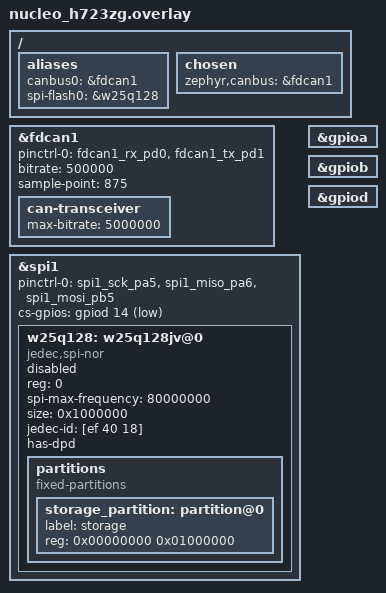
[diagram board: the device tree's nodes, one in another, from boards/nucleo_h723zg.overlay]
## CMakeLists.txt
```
# SPDX-License-Identifier: Apache-2.0

cmake_minimum_required(VERSION 3.20.0)

# Roadio firmware application
find_package(Zephyr REQUIRED HINTS $ENV{ZEPHYR_BASE})
project(roadio_firmware VERSION 0.1.0)

# Application source files
target_sources(app PRIVATE
    src/main.c
)

# Include directories
# target_include_directories(app PRIVATE
#     src/
# )
```

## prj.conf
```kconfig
# Roadio Firmware Configuration
# Zephyr v4.3.0 - Nucleo-H723ZG

# ========================================
# Kernel Configuration
# ========================================
CONFIG_MAIN_STACK_SIZE=4096
CONFIG_HEAP_MEM_POOL_SIZE=8192

# ========================================
# Logging Configuration
# ========================================
CONFIG_LOG=y
CONFIG_LOG_MODE_IMMEDIATE=y
CONFIG_LOG_DEFAULT_LEVEL=3

# ========================================
# Console/Shell Configuration
# ========================================
CONFIG_CONSOLE=y
CONFIG_UART_CONSOLE=y
CONFIG_SERIAL=y

# Optional: Enable shell for debugging/testing
CONFIG_SHELL=y
CONFIG_SHELL_BACKEND_SERIAL=y
CONFIG_SHELL_PROMPT_UART="roadio:~$ "

# ========================================
# CAN/FDCAN Configuration
# ========================================
CONFIG_CAN=y
CONFIG_CAN_INIT_PRIORITY=80

# Enable CAN shell for testing (optional - can disable in production)
CONFIG_CAN_SHELL=y

# CAN ISO-TP (Transport Protocol) for multi-frame messages
# Useful for UDS/OBD diagnostics
CONFIG_ISOTP=y

# ========================================
# GPIO Configuration
# ========================================
CONFIG_GPIO=y

# ========================================
# SPI Configuration (for W25Q128 flash)
# ========================================
CONFIG_SPI=y

# ========================================
# Flash & Storage Configuration
# ========================================
CONFIG_FLASH=y
CONFIG_FLASH_MAP=y
CONFIG_FLASH_PAGE_LAYOUT=y

# SPI NOR flash support (for W25Q128)
CONFIG_SPI_NOR=y
CONFIG_SPI_NOR_FLASH_LAYOUT_PAGE_SIZE=4096

# File system support
CONFIG_FILE_SYSTEM=y
CONFIG_FILE_SYSTEM_LITTLEFS=y

# Non-Volatile Storage (NVS) - lightweight key-value storage
CONFIG_NVS=y
CONFIG_NVS_LOG_LEVEL_DBG=n

# Optional: Flash simulator for testing (disable for production)
# CONFIG_FLASH_SIMULATOR=y

# ========================================
# Networking Configuration (for future use)
# ========================================
# Uncomment when adding network features (nRF7002 Wi-Fi, etc.)
# CONFIG_NETWORKING=y
# CONFIG_NET_IPV4=y
# CONFIG_NET_IPV6=y
# CONFIG_NET_TCP=y
# CONFIG_NET_UDP=y
# CONFIG_NET_DHCPV4=y

# ========================================
# USB Configuration (optional)
# ========================================
# Uncomment if using USB for console or data transfer
# CONFIG_USB_DEVICE_STACK=y
# CONFIG_USB_DEVICE_PRODUCT="Roadio OBD-II Device"
# CONFIG_USB_DEVICE_VID=0x2FE3
# CONFIG_USB_DEVICE_PID=0x0001

# ========================================
# Power Management (optional)
# ========================================
# Uncomment for low-power applications
# CONFIG_PM=y
# CONFIG_PM_DEVICE=y

# ========================================
# Watchdog (recommended for production)
# ========================================
# CONFIG_WATCHDOG=y
# CONFIG_WDT_DISABLE_AT_BOOT=n

# ========================================
# System Clock Configuration
# ========================================
# STM32H7 can run up to 550 MHz
# Default is usually fine, adjust if needed
# CONFIG_SYS_CLOCK_HW_CYCLES_PER_SEC=550000000

# ========================================
# Debug Configuration
# ========================================
# Enable for development, disable for production
CONFIG_DEBUG=y
CONFIG_DEBUG_OPTIMIZATIONS=y

# Assert configuration
CONFIG_ASSERT=y
CONFIG_ASSERT_LEVEL=2

# ========================================
# Thread Configuration
# ========================================
CONFIG_THREAD_NAME=y
CONFIG_THREAD_STACK_INFO=y

# ========================================
# Memory Protection (optional)
# ========================================
# CONFIG_ARM_MPU=y

# ========================================
# POSIX API (if needed for portability)
# ========================================
# CONFIG_POSIX_API=y
```

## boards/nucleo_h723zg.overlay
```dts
/*
 * Devicetree overlay for Nucleo-H723ZG board
 * Roadio hardware configuration
 *
 * Hardware components:
 * - SN65HVD230 CAN transceiver (connected to FDCAN1)
 * - W25Q128 external SPI flash (128 Mbit / 16 MB)
 * - LM2596 DC-DC buck converter (external power management)
 *
 * IMPORTANT: Verify actual pin connections match your hardware wiring!
 * Update pin assignments below to match your specific setup.
 */

/ {
	aliases {
		/* Define aliases for easy reference in application code */
		canbus0 = &fdcan1;
		spi-flash0 = &w25q128;
	};

	/* Choose CAN as the default console (optional - can use UART instead) */
	chosen {
		zephyr,canbus = &fdcan1;
	};
};

/*
 * FDCAN1 Configuration
 *
 * Default pins (verify against your actual wiring):
 * - TX: PD1 (Arduino D54)
 * - RX: PD0 (Arduino D55)
 *
 * SN65HVD230 transceiver connections:
 *   STM32 TX (PD1) -> CAN TX (pin 1)
 *   STM32 RX (PD0) -> CAN RX (pin 4)
 *   CAN H/L -> to vehicle OBD-II via DB9 adapter
 *
 * NOTE: OBD-II CAN is typically on pins 6 (CAN-H) and 14 (CAN-L) of the OBD connector.
 * Verify your DB9<->OBD2 cable pinout!
 */
&fdcan1 {
	status = "okay";
	pinctrl-0 = <&fdcan1_rx_pd0 &fdcan1_tx_pd1>;
	pinctrl-names = "default";

	/*
	 * CAN bus timing configuration:
	 * - bitrate: 500 kbit/s (standard OBD-II speed)
	 * - sample-point: 87.5% (recommended for automotive CAN)
	 * Adjust if your vehicle uses different speed (125k, 250k, 500k, 1000k common)
	 * If not specified, defaults to CONFIG_CAN_DEFAULT_BITRATE (usually 125k or 500k)
	 */
	bitrate = <500000>;
	sample-point = <875>;

	can-transceiver {
		max-bitrate = <5000000>; /* SN65HVD230 supports up to 1 Mbps for CAN, 5Mbps for CAN-FD */
	};
};

/*
 * SPI1 Configuration for W25Q128 External Flash
 *
 * Default pins (verify against your actual wiring):
 * - SCK:  PA5  (Arduino D13, Morpho CN7-10)
 * - MISO: PA6  (Arduino D12, Morpho CN7-12)
 * - MOSI: PB5  (Arduino D4, Morpho CN7-29)
 * - CS:   PD14 (Morpho CN7-16) - adjust as needed
 *
 * Note: Board default uses PB5 for MOSI. If using Arduino connector,
 * you may want PA7 instead - change pinctrl-0 accordingly.
 *
 * W25Q128 module connections:
 *   VCC  -> 3.3V
 *   GND  -> GND
 *   DI   -> MOSI (PB5)
 *   DO   -> MISO (PA6)
 *   CLK  -> SCK  (PA5)
 *   CS   -> PD14 (or your chosen CS pin)
 */
&spi1 {
	status = "okay";
	pinctrl-0 = <&spi1_sck_pa5 &spi1_miso_pa6 &spi1_mosi_pb5>;
	pinctrl-names = "default";
	cs-gpios = <&gpiod 14 GPIO_ACTIVE_LOW>;  /* CS on PD14 - adjust to match your wiring */

	w25q128: w25q128jv@0 {
		compatible = "jedec,spi-nor";
		reg = <0>;
		spi-max-frequency = <80000000>;  /* W25Q128JV supports up to 133 MHz, start conservative */
		size = <0x1000000>;  /* 128 Mbit = 16 MB = 0x1000000 bytes */
		jedec-id = [ef 40 18];  /* Winbond W25Q128 JEDEC ID */
		has-dpd;  /* Deep Power-Down support */
		status = "disabled";  /* Enable after wiring up hardware */

		/*
		 * Flash partitions for storage
		 * Adjust based on your firmware/data storage needs
		 */
		partitions {
			compatible = "fixed-partitions";
			#address-cells = <1>;
			#size-cells = <1>;

			/*
			 * Storage partition for application data
			 * Using LittleFS or NVS (Non-Volatile Storage)
			 * Size: 16 MB (entire flash for now)
			 */
			storage_partition: partition@0 {
				label = "storage";
				reg = <0x00000000 0x01000000>;  /* 16 MB */
			};
		};
	};
};

/*
 * Optional: Configure USART3 for debug console (if not using CAN)
 * Default Nucleo serial is on USART3 via ST-Link USB
 *
 * Uncomment if you want UART debug output:
 */
/*
&usart3 {
	status = "okay";
	pinctrl-0 = <&usart3_tx_pd8 &usart3_rx_pd9>;
	pinctrl-names = "default";
	current-speed = <115200>;
};
*/

/*
 * Enable GPIO ports used by peripherals
 */
&gpioa {
	status = "okay";
};

&gpiob {
	status = "okay";
};

&gpiod {
	status = "okay";
};

/*
 * Optional: QSPI configuration for W25Q128
 *
 * If you want to use QSPI instead of SPI for faster flash access,
 * uncomment and configure this section. Requires different wiring:
 *
 * QSPI pins on STM32H723:
 *   CLK:  PB2
 *   NCS:  PB6
 *   IO0:  PD11
 *   IO1:  PD12
 *   IO2:  PE2
 *   IO3:  PD13
 */
/*
&quadspi {
	status = "okay";
	pinctrl-0 = <&quadspi_clk_pb2 &quadspi_bk1_ncs_pb6
	             &quadspi_bk1_io0_pd11 &quadspi_bk1_io1_pd12
	             &quadspi_bk1_io2_pe2 &quadspi_bk1_io3_pd13>;
	pinctrl-names = "default";

	w25q128: w25q128jv@0 {
		compatible = "st,stm32-qspi-nor";
		reg = <0>;
		qspi-max-frequency = <80000000>;
		size = <0x1000000>;
		jedec-id = [ef 40 18];
		status = "okay";

		partitions {
			compatible = "fixed-partitions";
			#address-cells = <1>;
			#size-cells = <1>;

			storage_partition: partition@0 {
				label = "storage";
				reg = <0x00000000 0x01000000>;
			};
		};
	};
};
*/
```

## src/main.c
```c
/*
 * Roadio Firmware - Main Application
 * Target: ST Nucleo-H723ZG
 * Zephyr RTOS v4.3.0
 *
 * Hardware:
 * - SN65HVD230 CAN transceiver -> FDCAN1
 * - W25Q128 SPI flash (16 MB) -> SPI1
 * - LM2596 buck converter (power supply)
 */

#include <zephyr/kernel.h>
#include <zephyr/device.h>
#include <zephyr/drivers/can.h>
#include <zephyr/drivers/gpio.h>
#include <zephyr/drivers/flash.h>
#include <zephyr/logging/log.h>
#include <zephyr/storage/flash_map.h>
#include <zephyr/fs/fs.h>
#include <zephyr/fs/littlefs.h>

LOG_MODULE_REGISTER(roadio, LOG_LEVEL_INF);

// CAN device - defined in devicetree overlay
#define CAN_NODE DT_ALIAS(canbus0)

// External flash device
#define FLASH_NODE DT_ALIAS(spi_flash0)

// CAN message filter for OBD-II (example: filter for diagnostic responses)
static const struct can_filter obd_filter = {
	.flags = 0,       /* Standard 11-bit ID (CAN_FILTER_IDE not set) */
	.id = 0x7E8,      /* OBD-II standard response ID */
	.mask = 0x7F8,    /* Match 0x7E8-0x7EF */
};

// CAN callback for received messages
static void can_rx_callback(const struct device *dev, struct can_frame *frame,
			     void *user_data)
{
	ARG_UNUSED(dev);
	ARG_UNUSED(user_data);

	LOG_INF("CAN RX: ID=0x%03x DLC=%d", frame->id, frame->dlc);
	LOG_HEXDUMP_INF(frame->data, frame->dlc, "Data:");
}

// CAN state change callback
static void can_state_change_callback(const struct device *dev,
				      enum can_state state,
				      struct can_bus_err_cnt err_cnt,
				      void *user_data)
{
	ARG_UNUSED(dev);
	ARG_UNUSED(user_data);

	LOG_INF("CAN state changed: %d (TX err: %d, RX err: %d)",
		state, err_cnt.tx_err_cnt, err_cnt.rx_err_cnt);

	if (state == CAN_STATE_BUS_OFF) {
		LOG_ERR("CAN bus-off! Manual recovery required (stop/start).");
		// Note: can_recover() may not be available in all drivers
	}
}

// Initialize CAN interface
static int init_can(void)
{
	const struct device *can_dev = DEVICE_DT_GET(CAN_NODE);
	int ret;

	if (!device_is_ready(can_dev)) {
		LOG_ERR("CAN device not ready");
		return -ENODEV;
	}

	LOG_INF("Initializing CAN on %s", can_dev->name);

	// Set CAN mode to normal (loopback mode for testing without bus)
#ifdef CONFIG_CAN_LOOPBACK
	ret = can_set_mode(can_dev, CAN_MODE_LOOPBACK);
	LOG_INF("CAN loopback mode enabled for testing");
#else
	ret = can_set_mode(can_dev, CAN_MODE_NORMAL);
#endif

	if (ret != 0) {
		LOG_ERR("Failed to set CAN mode: %d", ret);
		return ret;
	}

	// Register state change callback
	can_set_state_change_callback(can_dev, can_state_change_callback, NULL);

	// Add receive filter for OBD-II responses
	ret = can_add_rx_filter(can_dev, can_rx_callback, NULL, &obd_filter);
	if (ret < 0) {
		LOG_ERR("Failed to add CAN RX filter: %d", ret);
		return ret;
	}

	// Start CAN controller
	ret = can_start(can_dev);
	if (ret != 0) {
		LOG_ERR("Failed to start CAN: %d", ret);
		return ret;
	}

	LOG_INF("CAN initialized successfully");
	return 0;
}

// Initialize external flash
static int init_flash(void)
{
#if DT_HAS_COMPAT_STATUS_OKAY(jedec_spi_nor)
	const struct device *flash_dev = DEVICE_DT_GET(DT_ALIAS(spi_flash0));
	int ret;

	if (!device_is_ready(flash_dev)) {
		LOG_WRN("External flash device not ready (check wiring)");
		return -ENODEV;
	}

	uint64_t flash_size = 0;

	LOG_INF("External flash initialized: %s", flash_dev->name);

	ret = flash_get_size(flash_dev, &flash_size);
	if (ret == 0) {
		LOG_INF("Flash size: %llu bytes", flash_size);
	}

	// Test flash access (optional)
	uint8_t test_data[16];
	ret = flash_read(flash_dev, 0, test_data, sizeof(test_data));
	if (ret == 0) {
		LOG_HEXDUMP_DBG(test_data, sizeof(test_data), "Flash read @ 0x00:");
	}

	return 0;
#else
	LOG_INF("External flash not configured in devicetree (see overlay file)");
	return -ENOTSUP;
#endif
}

// Main application entry point
int main(void)
{
	int ret;

	uint32_t version = sys_kernel_version_get();

	LOG_INF("==========================================");
	LOG_INF("Roadio Firmware Starting...");
	LOG_INF("Board: Nucleo-H723ZG");
	LOG_INF("Zephyr Version: %u.%u.%u",
		SYS_KERNEL_VER_MAJOR(version),
		SYS_KERNEL_VER_MINOR(version),
		SYS_KERNEL_VER_PATCHLEVEL(version));
	LOG_INF("==========================================");

	// Initialize CAN bus
	ret = init_can();
	if (ret != 0) {
		LOG_ERR("CAN initialization failed: %d", ret);
		// Continue anyway for now
	}

	// Initialize external flash
	ret = init_flash();
	if (ret != 0) {
		LOG_WRN("Flash initialization failed or not available: %d", ret);
	}

	// Main application loop
	LOG_INF("Entering main loop...");

	while (1) {
		// Heartbeat
		LOG_DBG("Heartbeat");

		/* TODO: Add application logic here:
		 * - Read OBD-II data from CAN bus
		 * - Process vehicle data
		 * - Store data to flash
		 * - Communicate over network (Wi-Fi)
		 * - etc.
		 */

		k_sleep(K_SECONDS(5));
	}

	return 0;
}
```
